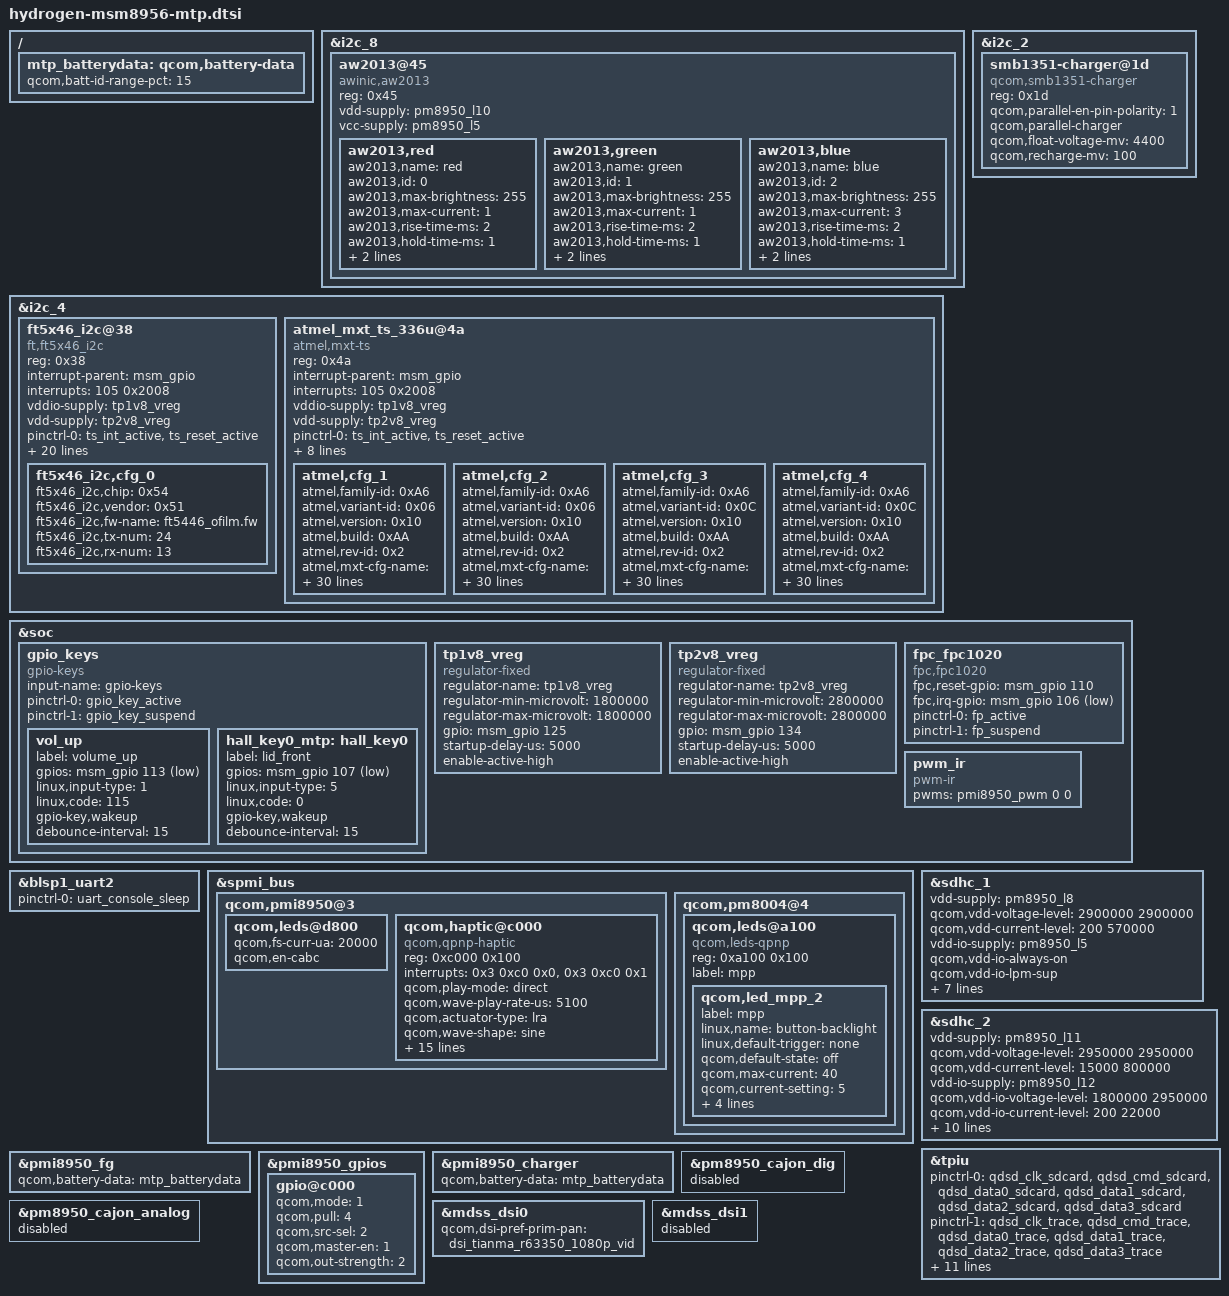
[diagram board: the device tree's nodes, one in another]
/*
 * Copyright (c) 2015, The Linux Foundation. All rights reserved.
 * Copyright (C) 2016 XiaoMi, Inc.
 *
 * This program is free software; you can redistribute it and/or modify
 * it under the terms of the GNU General Public License version 2 and
 * only version 2 as published by the Free Software Foundation.
 *
 * This program is distributed in the hope that it will be useful,
 * but WITHOUT ANY WARRANTY; without even the implied warranty of
 * MERCHANTABILITY or FITNESS FOR A PARTICULAR PURPOSE.  See the
 * GNU General Public License for more details.
 */

#include "msm8976-pinctrl.dtsi"
#include "msm8976-camera-sensor-mtp.dtsi"
#include "msm8976-mdss-mtp.dtsi"

&i2c_8 {
	aw2013@45 {
		compatible = "awinic,aw2013";
		reg = <0x45>;
		vdd-supply = <&pm8950_l10>;
		vcc-supply = <&pm8950_l5>;

		aw2013,red {
			aw2013,name = "red";
			aw2013,id = <0>;
			aw2013,max-brightness = <255>;
			aw2013,max-current = <1>;
			aw2013,rise-time-ms = <2>;
			aw2013,hold-time-ms = <1>;
			aw2013,fall-time-ms = <2>;
			aw2013,off-time-ms = <1>;
		};

		aw2013,green {
			aw2013,name = "green";
			aw2013,id = <1>;
			aw2013,max-brightness = <255>;
			aw2013,max-current = <1>;
			aw2013,rise-time-ms = <2>;
			aw2013,hold-time-ms = <1>;
			aw2013,fall-time-ms = <2>;
			aw2013,off-time-ms = <1>;
		};

		aw2013,blue {
			aw2013,name = "blue";
			aw2013,id = <2>;
			aw2013,max-brightness = <255>;
			aw2013,max-current = <3>;
			aw2013,rise-time-ms = <2>;
			aw2013,hold-time-ms = <1>;
			aw2013,fall-time-ms = <2>;
			aw2013,off-time-ms = <1>;
		};
	};
};

&i2c_4 { /* BLSP1 QUP4 */
	ft5x46_i2c@38 {
		compatible = "ft,ft5x46_i2c";
		reg = <0x38>;
		interrupt-parent = <&msm_gpio>;
		interrupts = <105 0x2008>;
		vddio-supply = <&tp1v8_vreg>;
		vdd-supply = <&tp2v8_vreg>;
		/* pins used by touchscreen */
		pinctrl-names = "pmx_ts_active","pmx_ts_suspend";
		pinctrl-0 = <&ts_int_active &ts_reset_active>;
		pinctrl-1 = <&ts_int_suspend &ts_reset_suspend>;
		ft5x46_i2c,i2c-pull-up;
		ft5x46_i2c,irqflags = <0x2008>;
		ft5x46_i2c,x-max = <1080>;
		ft5x46_i2c,y-max = <1920>;
		ft5x46_i2c,z-max = <255>;
		ft5x46_i2c,w-max = <200>;
		ft5x46_i2c,reset-gpio = <&msm_gpio 97 0x00>;
		ft5x46_i2c,irq-gpio = <&msm_gpio 105 0x2008>;
		ft5x46_i2c,landing-jiffies = <1000>;
		ft5x46_i2c,landing-threshold = <16>;
		ft5x46_i2c,staying-threshold = <8>;
		ft5x46_i2c,raw-min = <7000>;
		ft5x46_i2c,raw-max = <10000>;
		ft5x46_i2c,fw-delay-55-ms = <2>;
		ft5x46_i2c,fw-delay-aa-ms = <2>;
		ft5x46_i2c,fw-upgrade-id1 = <0x54>;
		ft5x46_i2c,fw-upgrade-id2 = <0x2C>;
		ft5x46_i2c,fw-delay-readid-ms = <20>;
		ft5x46_i2c,firmware-array-size = <1>;
		ft5x46_i2c,cfg_0 {
			ft5x46_i2c,chip = <0x54>;
			ft5x46_i2c,vendor = <0x51>;
			ft5x46_i2c,fw-name = "ft5446_ofilm.fw";
			ft5x46_i2c,tx-num = <24>;
			ft5x46_i2c,rx-num = <13>;
		};
	};
	atmel_mxt_ts_336u@4a {
		compatible = "atmel,mxt-ts";
		reg = <0x4a>;
		interrupt-parent = <&msm_gpio>;
		interrupts = <105 0x2008>;
		vddio-supply = <&tp1v8_vreg>;
		vdd-supply = <&tp2v8_vreg>;
		/* pins used by touchscreen */
		pinctrl-names = "pmx_ts_active","pmx_ts_suspend";
		pinctrl-0 = <&ts_int_active &ts_reset_active>;
		pinctrl-1 = <&ts_int_suspend &ts_reset_suspend>;
		atmel,reset-gpio = <&msm_gpio 97 0x00>;
		atmel,irq-gpio = <&msm_gpio 105 0x2008>;
		atmel,mxt-fw-name = "mXT336UL00AA.fw";
		atmel,config-array-size = <4>;
		atmel,default-config = <2>;
		atmel,irqflags = <0x2008>;
		atmel,vendor-id-byte = /bits/ 8 <0 3>;
		atmel,cfg_1 {
			atmel,family-id = <0xA6>;
			atmel,variant-id = <0x06>;
			atmel,version = <0x10>;
			atmel,build = <0xAA>;
			atmel,rev-id = <0x2>;
			atmel,mxt-cfg-name = "mxt_336u_biel_hw1_config.fw";
			atmel,vendor-id = /bits/ 8 <0x31 0x31>; /* Biel HW ver 1 */
			atmel,key-codes = <158 102 139>;
			atmel,selfintthr-stylus = <0>;
			atmel,t71-tchthr-pos = <22>;
			atmel,self-chgtime-min = <0>;
			atmel,self-chgtime-max = <0>;
			atmel,mult-intthr-sensitive = <12>;
			atmel,mult-intthr-not-sensitive = <17>;
			atmel,atchthr-sensitive = <6>;
			atmel,mult-tchthr-sensitive = <0>;
			atmel,mult-tchthr-not-sensitive = <0>;
			atmel,wake-up-self-adcx = <16>;
			atmel,support-wakeup-gesture;
			atmel,xycfg = <0>;
			atmel,ysize = <0x11>;
			atmel,yrange-lsb = <0x32>;
			atmel,yrange-msb = <0x05>;
			atmel,tchthr = <0x0f>;
			atmel,tchhyst = <0x05>;
			atmel,intthr = <0>;
			atmel,intthrhyst = <0>;
			atmel,xtchthr = <0x0c>;
			atmel,xtchhyst = <0x03>;
			atmel,intthrx = <0>;
			atmel,intthrhystx = <0>;
			atmel,ytchthr = <0x0c>;
			atmel,ytchhyst = <0x03>;
			atmel,intthry = <0>;
			atmel,intthrhysty = <0>;
		};
		atmel,cfg_2 {
			atmel,family-id = <0xA6>;
			atmel,variant-id = <0x06>;
			atmel,version = <0x10>;
			atmel,build = <0xAA>;
			atmel,rev-id = <0x2>;
			atmel,mxt-cfg-name = "mxt_336u_biel_hw2_config.fw";
			atmel,vendor-id = /bits/ 8 <0x31 0x32>; /* Biel HW ver 2 */
			atmel,key-codes = <158 102 139>;
			atmel,selfintthr-stylus = <0>;
			atmel,t71-tchthr-pos = <22>;
			atmel,self-chgtime-min = <0>;
			atmel,self-chgtime-max = <0>;
			atmel,mult-intthr-sensitive = <12>;
			atmel,mult-intthr-not-sensitive = <17>;
			atmel,atchthr-sensitive = <6>;
			atmel,mult-tchthr-sensitive = <0>;
			atmel,mult-tchthr-not-sensitive = <0>;
			atmel,wake-up-self-adcx = <16>;
			atmel,support-wakeup-gesture;
			atmel,xycfg = <0>;
			atmel,ysize = <0x11>;
			atmel,yrange-lsb = <0x32>;
			atmel,yrange-msb = <0x05>;
			atmel,tchthr = <0x0f>;
			atmel,tchhyst = <0x05>;
			atmel,intthr = <0>;
			atmel,intthrhyst = <0>;
			atmel,xtchthr = <0x0c>;
			atmel,xtchhyst = <0x03>;
			atmel,intthrx = <0>;
			atmel,intthrhystx = <0>;
			atmel,ytchthr = <0x0c>;
			atmel,ytchhyst = <0x03>;
			atmel,intthry = <0>;
			atmel,intthrhysty = <0>;
		};
		atmel,cfg_3 {
			atmel,family-id = <0xA6>;
			atmel,variant-id = <0x0C>;
			atmel,version = <0x10>;
			atmel,build = <0xAA>;
			atmel,rev-id = <0x2>;
			atmel,mxt-cfg-name = "mxt_336ul_biel_auo_config.fw";
			atmel,vendor-id = /bits/ 8 <0x31 0x33>; /* Biel+AUO HW ver 3 */
			atmel,key-codes = <158 102 139>;
			atmel,selfintthr-stylus = <0>;
			atmel,t71-tchthr-pos = <22>;
			atmel,self-chgtime-min = <0>;
			atmel,self-chgtime-max = <0>;
			atmel,mult-intthr-sensitive = <12>;
			atmel,mult-intthr-not-sensitive = <17>;
			atmel,atchthr-sensitive = <6>;
			atmel,mult-tchthr-sensitive = <0>;
			atmel,mult-tchthr-not-sensitive = <0>;
			atmel,wake-up-self-adcx = <16>;
			atmel,support-wakeup-gesture;
			atmel,xycfg = <0>;
			atmel,ysize = <0x11>;
			atmel,yrange-lsb = <0x32>;
			atmel,yrange-msb = <0x05>;
			atmel,tchthr = <0x0f>;
			atmel,tchhyst = <0x05>;
			atmel,intthr = <0>;
			atmel,intthrhyst = <0>;
			atmel,xtchthr = <0x0c>;
			atmel,xtchhyst = <0x03>;
			atmel,intthrx = <0>;
			atmel,intthrhystx = <0>;
			atmel,ytchthr = <0x0c>;
			atmel,ytchhyst = <0x03>;
			atmel,intthry = <0>;
			atmel,intthrhysty = <0>;
		};
		atmel,cfg_4 {
			atmel,family-id = <0xA6>;
			atmel,variant-id = <0x0C>;
			atmel,version = <0x10>;
			atmel,build = <0xAA>;
			atmel,rev-id = <0x2>;
			atmel,mxt-cfg-name = "mxt_336ul_biel_auo_config.fw";
			atmel,vendor-id = /bits/ 8 <0x31 0x31>; /* Biel+AUO HW ver 3 */
			atmel,key-codes = <158 102 139>;
			atmel,selfintthr-stylus = <0>;
			atmel,t71-tchthr-pos = <22>;
			atmel,self-chgtime-min = <0>;
			atmel,self-chgtime-max = <0>;
			atmel,mult-intthr-sensitive = <12>;
			atmel,mult-intthr-not-sensitive = <17>;
			atmel,atchthr-sensitive = <6>;
			atmel,mult-tchthr-sensitive = <0>;
			atmel,mult-tchthr-not-sensitive = <0>;
			atmel,wake-up-self-adcx = <16>;
			atmel,support-wakeup-gesture;
			atmel,xycfg = <0>;
			atmel,ysize = <0x11>;
			atmel,yrange-lsb = <0x32>;
			atmel,yrange-msb = <0x05>;
			atmel,tchthr = <0x0f>;
			atmel,tchhyst = <0x05>;
			atmel,intthr = <0>;
			atmel,intthrhyst = <0>;
			atmel,xtchthr = <0x0c>;
			atmel,xtchhyst = <0x03>;
			atmel,intthrx = <0>;
			atmel,intthrhystx = <0>;
			atmel,ytchthr = <0x0c>;
			atmel,ytchhyst = <0x03>;
			atmel,intthry = <0>;
			atmel,intthrhysty = <0>;
		};
	};
};

&i2c_2 {
	/* Parallel-charger configuration */
	smb1351-charger@1d {
		compatible = "qcom,smb1351-charger";
		reg = <0x1d>;
		qcom,parallel-en-pin-polarity = <1>;
		qcom,parallel-charger;
		qcom,float-voltage-mv = <4400>;
		qcom,recharge-mv = <100>;
	};
};

&soc {
	gpio_keys {
		compatible = "gpio-keys";
		input-name = "gpio-keys";
		pinctrl-names = "tlmm_gpio_key_active","tlmm_gpio_key_suspend";
		pinctrl-0 = <&gpio_key_active>;
		pinctrl-1 = <&gpio_key_suspend>;

		vol_up {
			label = "volume_up";
			gpios = <&msm_gpio 113 0x1>;
			linux,input-type = <1>;
			linux,code = <115>;
			gpio-key,wakeup;
			debounce-interval = <15>;
		};

		hall_key0_mtp: hall_key0 {
			label = "lid_front";
			gpios = <&msm_gpio 107 0x1>;
			linux,input-type = <5>;
			linux,code = <0>;
			gpio-key,wakeup;
			debounce-interval = <15>;
		};
	};

	tp1v8_vreg: tp1v8_vreg {
		compatible = "regulator-fixed";
		regulator-name = "tp1v8_vreg";
		regulator-min-microvolt = <1800000>;
		regulator-max-microvolt = <1800000>;
		gpio = <&msm_gpio 125 0>;
		startup-delay-us = <5000>;
		enable-active-high;
	};

	tp2v8_vreg: tp2v8_vreg {
		compatible = "regulator-fixed";
		regulator-name = "tp2v8_vreg";
		regulator-min-microvolt = <2800000>;
		regulator-max-microvolt = <2800000>;
		gpio = <&msm_gpio 134 0>;
		startup-delay-us = <5000>;
		enable-active-high;
	};

	fpc_fpc1020 {
		compatible = "fpc,fpc1020";
		fpc,reset-gpio	= <&msm_gpio 110 0x00>;
		fpc,irq-gpio	= <&msm_gpio 106 0x2001>;
		pinctrl-names = "pmx_fp_active", "pmx_fp_suspend";
		pinctrl-0 = <&fp_active>;
		pinctrl-1 = <&fp_suspend>;
	};

	pwm_ir {
		compatible = "pwm-ir";
		pwms = <&pmi8950_pwm 0 0>;
	};
};

&blsp1_uart2 {
	status = "ok";
	pinctrl-names = "default";
	pinctrl-0 = <&uart_console_sleep>;
};


&spmi_bus {
	qcom,pmi8950@3 {
		qcom,leds@d800 {
			qcom,fs-curr-ua = <20000>;
			qcom,en-cabc;
		};

		qcom,haptic@c000 {
			compatible = "qcom,qpnp-haptic";
			reg = <0xc000 0x100>;
			interrupts = <0x3 0xc0 0x0>,
				<0x3 0xc0 0x1>;
			interrupt-names = "sc-irq", "play-irq";
			qcom,play-mode = "direct";
			qcom,wave-play-rate-us = <5100>;
			qcom,actuator-type = "lra";
			qcom,wave-shape = "sine";
			qcom,vmax-mv = <2088>;
			qcom,ilim-ma = <800>;
			qcom,sc-deb-cycles = <8>;
			qcom,int-pwm-freq-khz = <505>;
			qcom,en-brake;
			qcom,brake-pattern = [03 02 01 00];
			qcom,use-play-irq;
			qcom,use-sc-irq;
			qcom,wave-samples = [3e 3e 3e 3e 3e 3e 3e 3e];
			qcom,wave-rep-cnt = <1>;
			qcom,wave-samp-rep-cnt = <1>;
			qcom,lra-auto-res-mode="qwd";
			qcom,lra-high-z="opt1";
			qcom,lra-res-cal-period = <4>;
			qcom,misc-trim-error-rc19p2-clk-reg-present;
		};
	};

	qcom,pm8004@4 {
		qcom,leds@a100 {
                        compatible = "qcom,leds-qpnp";
                        reg = <0xa100 0x100>;
                        label = "mpp";
                        status = "okay";

                        qcom,led_mpp_2 {
                                label = "mpp";
                                linux,name = "button-backlight";
                                linux,default-trigger = "none";
                                qcom,default-state = "off";
                                qcom,max-current = <40>;
                                qcom,current-setting = <5>;
                                qcom,id = <6>;
                                qcom,mode = "manual";
                                qcom,source-sel = <1>;
                                qcom,mode-ctrl = <0x60>;
                        };
                };
	};
};

&sdhc_1 {
	vdd-supply = <&pm8950_l8>;
	qcom,vdd-voltage-level = <2900000 2900000>;
	qcom,vdd-current-level = <200 570000>;

	vdd-io-supply = <&pm8950_l5>;
	qcom,vdd-io-always-on;
	qcom,vdd-io-lpm-sup;
	qcom,vdd-io-voltage-level = <1800000 1800000>;
	qcom,vdd-io-current-level = <200 325000>;

	pinctrl-names = "active", "sleep";
	pinctrl-0 = <&sdc1_clk_on &sdc1_cmd_on &sdc1_data_on &sdc1_rclk_on>;
	pinctrl-1 = <&sdc1_clk_off &sdc1_cmd_off &sdc1_data_off &sdc1_rclk_off>;

	qcom,nonremovable;

	status = "ok";
};

&sdhc_2 {
	vdd-supply = <&pm8950_l11>;
	qcom,vdd-voltage-level = <2950000 2950000>;
	qcom,vdd-current-level = <15000 800000>;

	vdd-io-supply = <&pm8950_l12>;
	qcom,vdd-io-voltage-level = <1800000 2950000>;
	qcom,vdd-io-current-level = <200 22000>;

	pinctrl-names = "active", "sleep";
	pinctrl-0 = <&sdc2_clk_on &sdc2_cmd_on &sdc2_data_on &sdc2_cd_on>;
	pinctrl-1 = <&sdc2_clk_off &sdc2_cmd_off &sdc2_data_off &sdc2_cd_off>;

	#address-cells = <0>;
	interrupt-parent = <&sdhc_2>;
	interrupts = <0 1 2>;
	#interrupt-cells = <1>;
	interrupt-map-mask = <0xffffffff>;
	interrupt-map = <0 &intc 0 125 0
			1 &intc 0 221 0
			2 &msm_gpio 100 0>;
	interrupt-names = "hc_irq", "pwr_irq", "status_irq";
	cd-gpios = <&msm_gpio 100 0x1>;

	status = "ok";
};

/* CoreSight */
&tpiu {
	pinctrl-names = "sdcard", "trace", "swduart",
			"swdtrc", "jtag", "spmi";
	/* NIDnT */
	pinctrl-0 = <&qdsd_clk_sdcard &qdsd_cmd_sdcard
		     &qdsd_data0_sdcard &qdsd_data1_sdcard
		     &qdsd_data2_sdcard &qdsd_data3_sdcard>;
	pinctrl-1 = <&qdsd_clk_trace &qdsd_cmd_trace
		     &qdsd_data0_trace &qdsd_data1_trace
		     &qdsd_data2_trace &qdsd_data3_trace>;
	pinctrl-2 = <&qdsd_cmd_swduart &qdsd_data0_swduart
		     &qdsd_data1_swduart &qdsd_data2_swduart
		     &qdsd_data3_swduart>;
	pinctrl-3 = <&qdsd_clk_swdtrc &qdsd_cmd_swdtrc
		     &qdsd_data0_swdtrc &qdsd_data1_swdtrc
		     &qdsd_data2_swdtrc &qdsd_data3_swdtrc>;
	pinctrl-4 = <&qdsd_cmd_jtag &qdsd_data0_jtag
		     &qdsd_data1_jtag &qdsd_data2_jtag
		     &qdsd_data3_jtag>;
	pinctrl-5 = <&qdsd_clk_spmi &qdsd_cmd_spmi
		     &qdsd_data0_spmi &qdsd_data3_spmi>;
};

/{
	mtp_batterydata: qcom,battery-data {
		qcom,batt-id-range-pct = <15>;
		#include "batterydata-atl-4850mah.dtsi"
		#include "batterydata-coslight-4850mah.dtsi"
		#include "batterydata-itech-3020mah.dtsi"
	};
};

&pmi8950_fg {
	qcom,battery-data = <&mtp_batterydata>;
};

&pmi8950_gpios {
	gpio@c000 { /* GPIO 1 */
		/* INFARED_DRV */
		status = "okay";
		qcom,mode = <1>;         /* QPNP_PIN_MODE_DIG_OUT */
		qcom,pull = <4>;                        /*PULL DOWN 10uA*/
		qcom,src-sel = <2>;             /*SPECIAL FUNCTION 1*/
		qcom,master-en = <1>;           /*ENABLE GPIO*/
		qcom,out-strength = <2>;        /*Medium strength current*/
        };
};

&pmi8950_charger {
	qcom,battery-data = <&mtp_batterydata>;
};

&pm8950_cajon_dig {
	status = "disabled";
};

&pm8950_cajon_analog {
	status = "disabled";
};

&mdss_dsi0 {
	qcom,dsi-pref-prim-pan = <&dsi_tianma_r63350_1080p_vid>;
};

&mdss_dsi1{
	status = "disabled";
};
